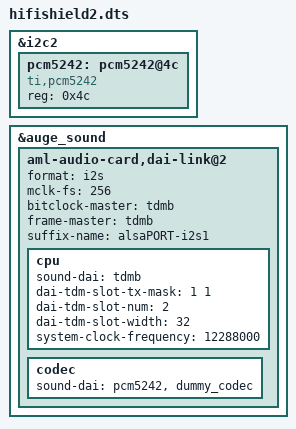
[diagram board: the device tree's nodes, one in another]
/dts-v1/;
/plugin/;

/ {
	fragment@0 {
		// i2c2 aliased with i2c0.
		target = <&i2c2>;

		__overlay__ {
			status = "okay";

			#address-cells = <1>;
			#size-cells = <0>;

			pcm5242: pcm5242@4c {
				compatible = "ti,pcm5242";
				reg = <0x4c>;
				#sound-dai-cells = <0>;
				status = "okay";

				/*
				AVDD-supply = <&reg_3v3_analog>;
				DVDD-supply = <&reg_1v8>;
				CPVDD-supply = <&reg_3v3>;
				*/
			};
		};
	};

	fragment@1 {
		target = <&auge_sound>;
		__overlay__ {
			aml-audio-card,dai-link@2 {
				status = "okay";
				format = "i2s";
				mclk-fs = <256>;
				bitclock-master = <&tdmb>;
				frame-master = <&tdmb>;
				suffix-name = "alsaPORT-i2s1";
				cpu {
					sound-dai = <&tdmb>;
					dai-tdm-slot-tx-mask = <1 1>;
					dai-tdm-slot-num = <2>;
					dai-tdm-slot-width = <32>;
					system-clock-frequency = <12288000>;
				};
				codec {
					sound-dai = <&pcm5242 &dummy_codec>;
				};
			};
		};
	};
};
